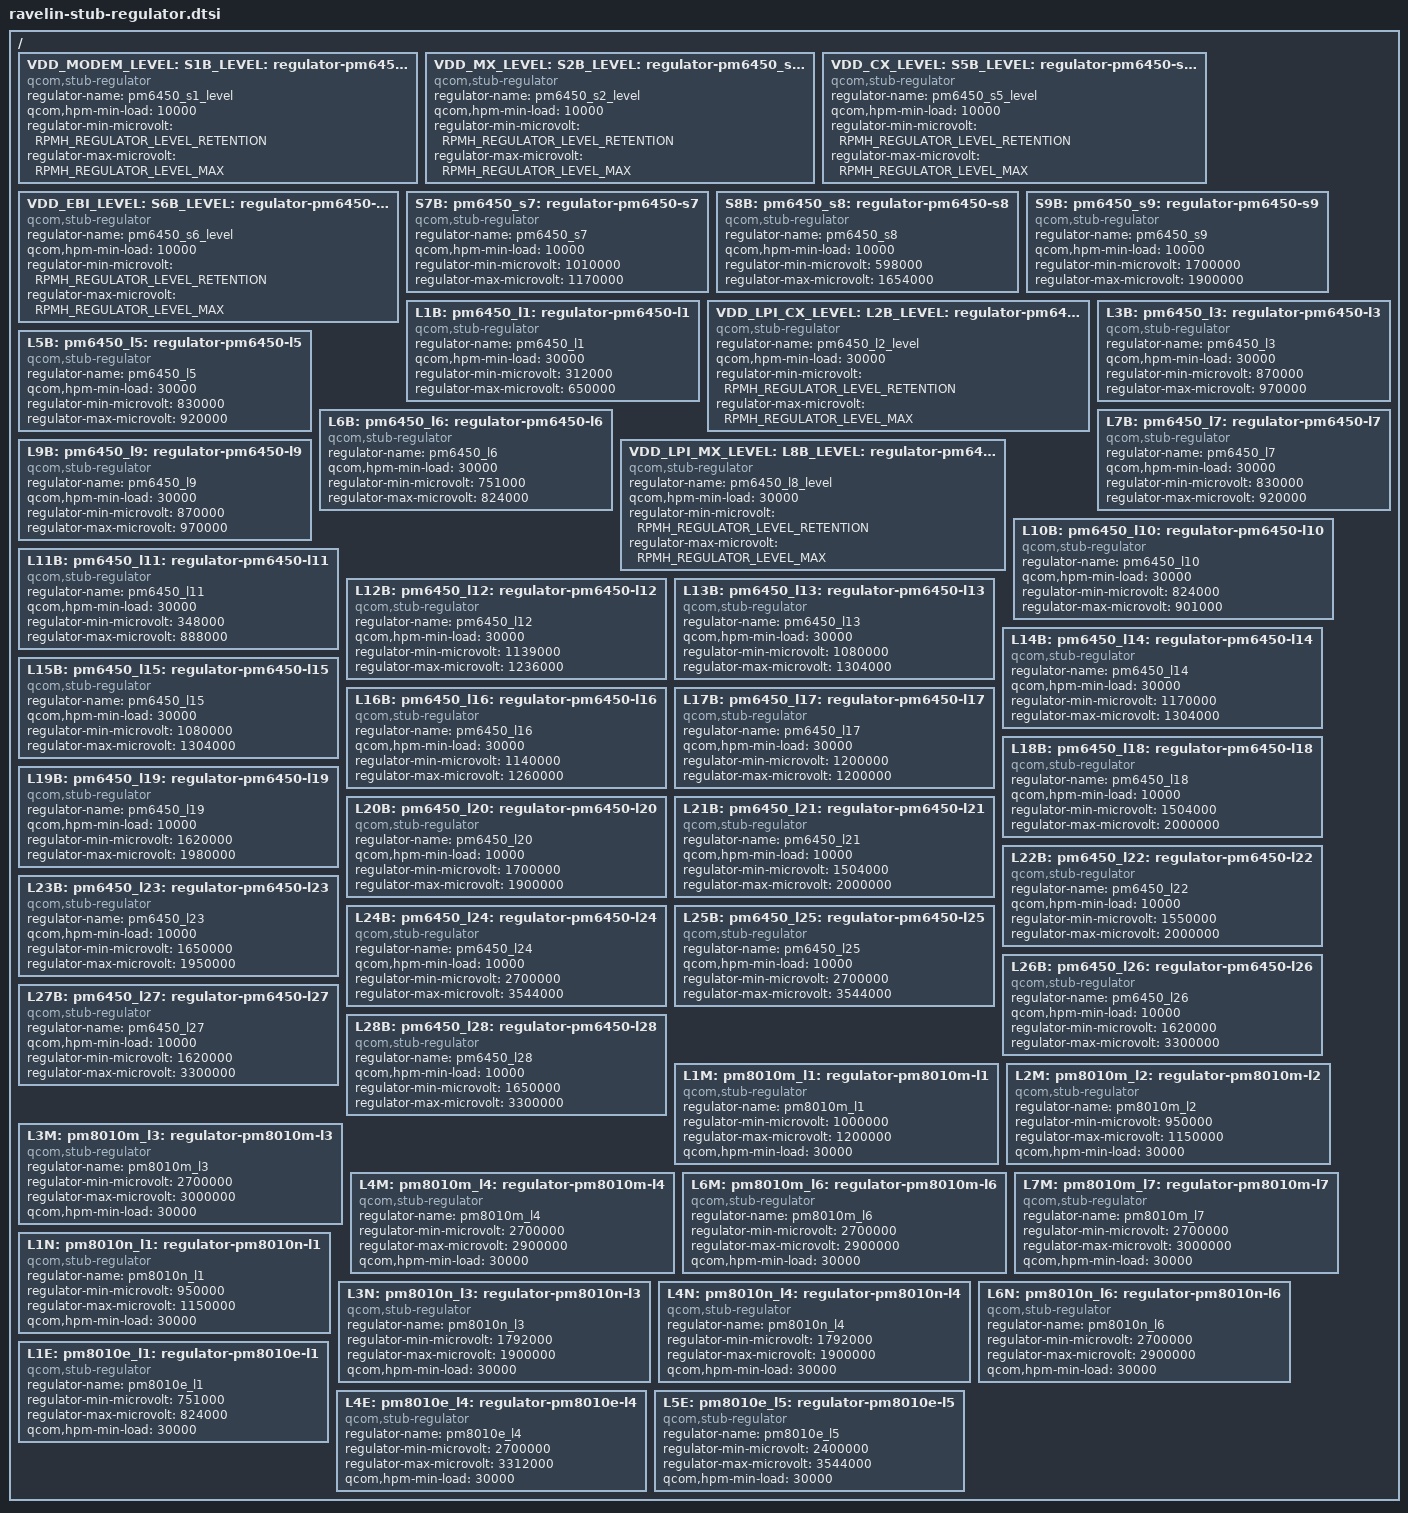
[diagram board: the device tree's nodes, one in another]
#include <dt-bindings/regulator/qcom,rpmh-regulator-levels.h>

/ {
	VDD_MODEM_LEVEL:
	S1B_LEVEL:
	pm6450_s1_level: regulator-pm6450-s1-level {
		compatible = "qcom,stub-regulator";
		regulator-name = "pm6450_s1_level";
		qcom,hpm-min-load = <10000>;
		regulator-min-microvolt =
			<RPMH_REGULATOR_LEVEL_RETENTION>;
		regulator-max-microvolt = <RPMH_REGULATOR_LEVEL_MAX>;
	};

	VDD_MX_LEVEL:
	S2B_LEVEL:
	pm6450_s2_level: regulator-pm6450_s2_level {
		compatible = "qcom,stub-regulator";
		regulator-name = "pm6450_s2_level";
		qcom,hpm-min-load = <10000>;
		regulator-min-microvolt = <RPMH_REGULATOR_LEVEL_RETENTION>;
		regulator-max-microvolt = <RPMH_REGULATOR_LEVEL_MAX>;
	};

	VDD_CX_LEVEL:
	S5B_LEVEL:
	pm6450_s5_level: regulator-pm6450-s5-level {
		compatible = "qcom,stub-regulator";
		regulator-name = "pm6450_s5_level";
		qcom,hpm-min-load = <10000>;
		regulator-min-microvolt =
			<RPMH_REGULATOR_LEVEL_RETENTION>;
		regulator-max-microvolt = <RPMH_REGULATOR_LEVEL_MAX>;
	};

	VDD_EBI_LEVEL:
	S6B_LEVEL:
	pm6450_s6: regulator-pm6450-s6-level {
		compatible = "qcom,stub-regulator";
		regulator-name = "pm6450_s6_level";
		qcom,hpm-min-load = <10000>;
		regulator-min-microvolt =
			<RPMH_REGULATOR_LEVEL_RETENTION>;
		regulator-max-microvolt = <RPMH_REGULATOR_LEVEL_MAX>;
	};

	S7B:
	pm6450_s7: regulator-pm6450-s7 {
		compatible = "qcom,stub-regulator";
		regulator-name = "pm6450_s7";
		qcom,hpm-min-load = <10000>;
		regulator-min-microvolt = <1010000>;
		regulator-max-microvolt = <1170000>;
	};

	S8B:
	pm6450_s8: regulator-pm6450-s8 {
		compatible = "qcom,stub-regulator";
		regulator-name = "pm6450_s8";
		qcom,hpm-min-load = <10000>;
		regulator-min-microvolt = <598000>;
		regulator-max-microvolt = <1654000>;
	};

	S9B:
	pm6450_s9: regulator-pm6450-s9 {
		compatible = "qcom,stub-regulator";
		regulator-name = "pm6450_s9";
		qcom,hpm-min-load = <10000>;
		regulator-min-microvolt = <1700000>;
		regulator-max-microvolt = <1900000>;
	};

	L1B:
	pm6450_l1: regulator-pm6450-l1 {
		compatible = "qcom,stub-regulator";
		regulator-name = "pm6450_l1";
		qcom,hpm-min-load = <30000>;
		regulator-min-microvolt = <312000>;
		regulator-max-microvolt = <650000>;
	};

	VDD_LPI_CX_LEVEL:
	L2B_LEVEL:
	pm6450_l2_level: regulator-pm6450-l2-level {
		compatible = "qcom,stub-regulator";
		regulator-name = "pm6450_l2_level";
		qcom,hpm-min-load = <30000>;
		regulator-min-microvolt =
			<RPMH_REGULATOR_LEVEL_RETENTION>;
		regulator-max-microvolt = <RPMH_REGULATOR_LEVEL_MAX>;
	};

	L3B:
	pm6450_l3: regulator-pm6450-l3 {
		compatible = "qcom,stub-regulator";
		regulator-name = "pm6450_l3";
		qcom,hpm-min-load = <30000>;
		regulator-min-microvolt = <870000>;
		regulator-max-microvolt = <970000>;
	};

	L5B:
	pm6450_l5: regulator-pm6450-l5 {
		compatible = "qcom,stub-regulator";
		regulator-name = "pm6450_l5";
		qcom,hpm-min-load = <30000>;
		regulator-min-microvolt = <830000>;
		regulator-max-microvolt = <920000>;
	};

	L6B:
	pm6450_l6: regulator-pm6450-l6 {
		compatible = "qcom,stub-regulator";
		regulator-name = "pm6450_l6";
		qcom,hpm-min-load = <30000>;
		regulator-min-microvolt = <751000>;
		regulator-max-microvolt = <824000>;
	};

	L7B:
	pm6450_l7: regulator-pm6450-l7 {
		compatible = "qcom,stub-regulator";
		regulator-name = "pm6450_l7";
		qcom,hpm-min-load = <30000>;
		regulator-min-microvolt = <830000>;
		regulator-max-microvolt = <920000>;
	};

	VDD_LPI_MX_LEVEL:
	L8B_LEVEL:
	pm6450_l8_level: regulator-pm6450-l8-level {
		compatible = "qcom,stub-regulator";
		regulator-name = "pm6450_l8_level";
		qcom,hpm-min-load = <30000>;
		regulator-min-microvolt =
			<RPMH_REGULATOR_LEVEL_RETENTION>;
		regulator-max-microvolt = <RPMH_REGULATOR_LEVEL_MAX>;
	};

	L9B:
	pm6450_l9: regulator-pm6450-l9 {
		compatible = "qcom,stub-regulator";
		regulator-name = "pm6450_l9";
		qcom,hpm-min-load = <30000>;
		regulator-min-microvolt = <870000>;
		regulator-max-microvolt = <970000>;
	};

	L10B:
	pm6450_l10: regulator-pm6450-l10 {
		compatible = "qcom,stub-regulator";
		regulator-name = "pm6450_l10";
		qcom,hpm-min-load = <30000>;
		regulator-min-microvolt = <824000>;
		regulator-max-microvolt = <901000>;
	};

	L11B:
	pm6450_l11: regulator-pm6450-l11 {
		compatible = "qcom,stub-regulator";
		regulator-name = "pm6450_l11";
		qcom,hpm-min-load = <30000>;
		regulator-min-microvolt = <348000>;
		regulator-max-microvolt = <888000>;
	};

	L12B:
	pm6450_l12: regulator-pm6450-l12 {
		compatible = "qcom,stub-regulator";
		regulator-name = "pm6450_l12";
		qcom,hpm-min-load = <30000>;
		regulator-min-microvolt = <1139000>;
		regulator-max-microvolt = <1236000>;
	};

	L13B:
	pm6450_l13: regulator-pm6450-l13 {
		compatible = "qcom,stub-regulator";
		regulator-name = "pm6450_l13";
		qcom,hpm-min-load = <30000>;
		regulator-min-microvolt = <1080000>;
		regulator-max-microvolt = <1304000>;
	};

	L14B:
	pm6450_l14: regulator-pm6450-l14 {
		compatible = "qcom,stub-regulator";
		regulator-name = "pm6450_l14";
		qcom,hpm-min-load = <30000>;
		regulator-min-microvolt = <1170000>;
		regulator-max-microvolt = <1304000>;
	};

	L15B:
	pm6450_l15: regulator-pm6450-l15 {
		compatible = "qcom,stub-regulator";
		regulator-name = "pm6450_l15";
		qcom,hpm-min-load = <30000>;
		regulator-min-microvolt = <1080000>;
		regulator-max-microvolt = <1304000>;
	};

	L16B:
	pm6450_l16: regulator-pm6450-l16 {
		compatible = "qcom,stub-regulator";
		regulator-name = "pm6450_l16";
		qcom,hpm-min-load = <30000>;
		regulator-min-microvolt = <1140000>;
		regulator-max-microvolt = <1260000>;
	};

	L17B:
	pm6450_l17: regulator-pm6450-l17 {
		compatible = "qcom,stub-regulator";
		regulator-name = "pm6450_l17";
		qcom,hpm-min-load = <30000>;
		regulator-min-microvolt = <1200000>;
		regulator-max-microvolt = <1200000>;
	};

	L18B:
	pm6450_l18: regulator-pm6450-l18 {
		compatible = "qcom,stub-regulator";
		regulator-name = "pm6450_l18";
		qcom,hpm-min-load = <10000>;
		regulator-min-microvolt = <1504000>;
		regulator-max-microvolt = <2000000>;
	};

	L19B:
	pm6450_l19: regulator-pm6450-l19 {
		compatible = "qcom,stub-regulator";
		regulator-name = "pm6450_l19";
		qcom,hpm-min-load = <10000>;
		regulator-min-microvolt = <1620000>;
		regulator-max-microvolt = <1980000>;
	};

	L20B:
	pm6450_l20: regulator-pm6450-l20 {
		compatible = "qcom,stub-regulator";
		regulator-name = "pm6450_l20";
		qcom,hpm-min-load = <10000>;
		regulator-min-microvolt = <1700000>;
		regulator-max-microvolt = <1900000>;
	};

	L21B:
	pm6450_l21: regulator-pm6450-l21 {
		compatible = "qcom,stub-regulator";
		regulator-name = "pm6450_l21";
		qcom,hpm-min-load = <10000>;
		regulator-min-microvolt = <1504000>;
		regulator-max-microvolt = <2000000>;
	};

	L22B:
	pm6450_l22: regulator-pm6450-l22 {
		compatible = "qcom,stub-regulator";
		regulator-name = "pm6450_l22";
		qcom,hpm-min-load = <10000>;
		regulator-min-microvolt = <1550000>;
		regulator-max-microvolt = <2000000>;
	};

	L23B:
	pm6450_l23: regulator-pm6450-l23 {
		compatible = "qcom,stub-regulator";
		regulator-name = "pm6450_l23";
		qcom,hpm-min-load = <10000>;
		regulator-min-microvolt = <1650000>;
		regulator-max-microvolt = <1950000>;
	};

	L24B:
	pm6450_l24: regulator-pm6450-l24 {
		compatible = "qcom,stub-regulator";
		regulator-name = "pm6450_l24";
		qcom,hpm-min-load = <10000>;
		regulator-min-microvolt = <2700000>;
		regulator-max-microvolt = <3544000>;
	};

	L25B:
	pm6450_l25: regulator-pm6450-l25 {
		compatible = "qcom,stub-regulator";
		regulator-name = "pm6450_l25";
		qcom,hpm-min-load = <10000>;
		regulator-min-microvolt = <2700000>;
		regulator-max-microvolt = <3544000>;
	};

	L26B:
	pm6450_l26: regulator-pm6450-l26 {
		compatible = "qcom,stub-regulator";
		regulator-name = "pm6450_l26";
		qcom,hpm-min-load = <10000>;
		regulator-min-microvolt = <1620000>;
		regulator-max-microvolt = <3300000>;
	};

	L27B:
	pm6450_l27: regulator-pm6450-l27 {
		compatible = "qcom,stub-regulator";
		regulator-name = "pm6450_l27";
		qcom,hpm-min-load = <10000>;
		regulator-min-microvolt = <1620000>;
		regulator-max-microvolt = <3300000>;
	};

	L28B:
	pm6450_l28: regulator-pm6450-l28 {
		compatible = "qcom,stub-regulator";
		regulator-name = "pm6450_l28";
		qcom,hpm-min-load = <10000>;
		regulator-min-microvolt = <1650000>;
		regulator-max-microvolt = <3300000>;
	};

	L1M: pm8010m_l1: regulator-pm8010m-l1 {
		compatible = "qcom,stub-regulator";
		regulator-name = "pm8010m_l1";
		regulator-min-microvolt = <1000000>;
		regulator-max-microvolt = <1200000>;
		qcom,hpm-min-load = <30000>;
	};

	L2M: pm8010m_l2: regulator-pm8010m-l2 {
		compatible = "qcom,stub-regulator";
		regulator-name = "pm8010m_l2";
		regulator-min-microvolt = <950000>;
		regulator-max-microvolt = <1150000>;
		qcom,hpm-min-load = <30000>;
	};

	L3M: pm8010m_l3: regulator-pm8010m-l3 {
		compatible = "qcom,stub-regulator";
		regulator-name = "pm8010m_l3";
		regulator-min-microvolt = <2700000>;
		regulator-max-microvolt = <3000000>;
		qcom,hpm-min-load = <30000>;
	};

	L4M: pm8010m_l4: regulator-pm8010m-l4 {
		compatible = "qcom,stub-regulator";
		regulator-name = "pm8010m_l4";
		regulator-min-microvolt = <2700000>;
		regulator-max-microvolt = <2900000>;
		qcom,hpm-min-load = <30000>;
	};

	L6M: pm8010m_l6: regulator-pm8010m-l6 {
		compatible = "qcom,stub-regulator";
		regulator-name = "pm8010m_l6";
		regulator-min-microvolt = <2700000>;
		regulator-max-microvolt = <2900000>;
		qcom,hpm-min-load = <30000>;
	};

	L7M: pm8010m_l7: regulator-pm8010m-l7 {
		compatible = "qcom,stub-regulator";
		regulator-name = "pm8010m_l7";
		regulator-min-microvolt = <2700000>;
		regulator-max-microvolt = <3000000>;
		qcom,hpm-min-load = <30000>;
	};

	L1N: pm8010n_l1: regulator-pm8010n-l1 {
		compatible = "qcom,stub-regulator";
		regulator-name = "pm8010n_l1";
		regulator-min-microvolt = <950000>;
		regulator-max-microvolt = <1150000>;
		qcom,hpm-min-load = <30000>;
	};

	L3N: pm8010n_l3: regulator-pm8010n-l3 {
		compatible = "qcom,stub-regulator";
		regulator-name = "pm8010n_l3";
		regulator-min-microvolt = <1792000>;
		regulator-max-microvolt = <1900000>;
		qcom,hpm-min-load = <30000>;
	};

	L4N: pm8010n_l4: regulator-pm8010n-l4 {
		compatible = "qcom,stub-regulator";
		regulator-name = "pm8010n_l4";
		regulator-min-microvolt = <1792000>;
		regulator-max-microvolt = <1900000>;
		qcom,hpm-min-load = <30000>;
	};

	L6N: pm8010n_l6: regulator-pm8010n-l6 {
		compatible = "qcom,stub-regulator";
		regulator-name = "pm8010n_l6";
		regulator-min-microvolt = <2700000>;
		regulator-max-microvolt = <2900000>;
		qcom,hpm-min-load = <30000>;
	};

	L1E: pm8010e_l1: regulator-pm8010e-l1 {
		compatible = "qcom,stub-regulator";
		regulator-name = "pm8010e_l1";
		regulator-min-microvolt = <751000>;
		regulator-max-microvolt = <824000>;
		qcom,hpm-min-load = <30000>;
	};

	L4E: pm8010e_l4: regulator-pm8010e-l4 {
		compatible = "qcom,stub-regulator";
		regulator-name = "pm8010e_l4";
		regulator-min-microvolt = <2700000>;
		regulator-max-microvolt = <3312000>;
		qcom,hpm-min-load = <30000>;
	};

	L5E: pm8010e_l5: regulator-pm8010e-l5 {
		compatible = "qcom,stub-regulator";
		regulator-name = "pm8010e_l5";
		regulator-min-microvolt = <2400000>;
		regulator-max-microvolt = <3544000>;
		qcom,hpm-min-load = <30000>;
	};
};
